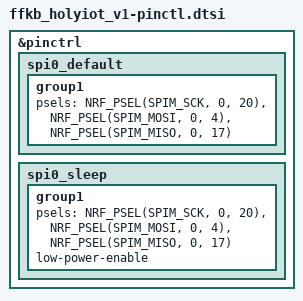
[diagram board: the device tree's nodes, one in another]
/*
 * Copyright (c) 2024 Sadek Baroudi
 * SPDX-License-Identifier: MIT
 */

/*
    SCK and MISO are "fake" pins, since this driver doesn't use those
*/
&pinctrl {
    spi0_default: spi0_default {
        group1 {
            psels = <NRF_PSEL(SPIM_SCK, 0, 20)>,
                <NRF_PSEL(SPIM_MOSI, 0, 4)>,
                <NRF_PSEL(SPIM_MISO, 0, 17)>;
        };
    };

    spi0_sleep: spi0_sleep {
        group1 {
            psels = <NRF_PSEL(SPIM_SCK, 0, 20)>,
                <NRF_PSEL(SPIM_MOSI, 0, 4)>,
                <NRF_PSEL(SPIM_MISO, 0, 17)>;
            low-power-enable;
        };
    };
};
